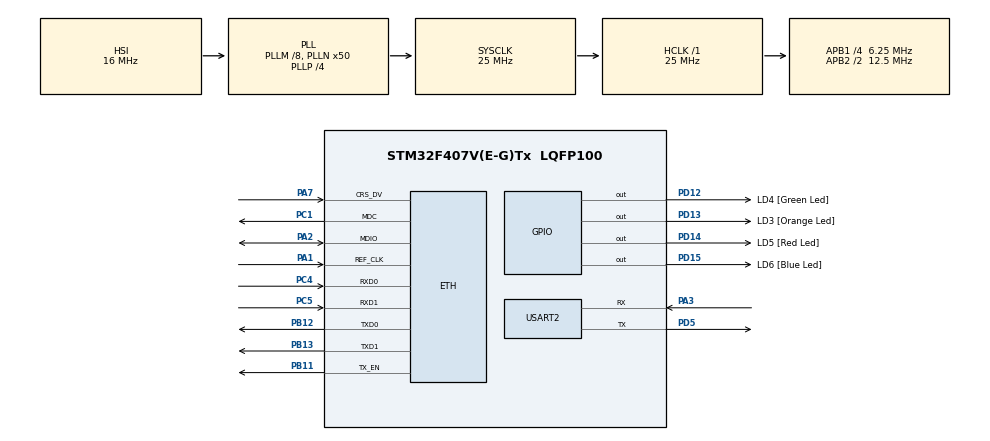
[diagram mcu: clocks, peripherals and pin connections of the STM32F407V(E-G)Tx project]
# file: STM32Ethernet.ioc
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Dma.Request0=USART2_TX
Dma.USART2_TX.0.Direction=DMA_MEMORY_TO_PERIPH
Dma.USART2_TX.0.FIFOMode=DMA_FIFOMODE_DISABLE
Dma.USART2_TX.0.Instance=DMA1_Stream6
Dma.USART2_TX.0.MemDataAlignment=DMA_MDATAALIGN_BYTE
Dma.USART2_TX.0.MemInc=DMA_MINC_ENABLE
Dma.USART2_TX.0.Mode=DMA_NORMAL
Dma.USART2_TX.0.PeriphDataAlignment=DMA_PDATAALIGN_BYTE
Dma.USART2_TX.0.PeriphInc=DMA_PINC_DISABLE
Dma.USART2_TX.0.Priority=DMA_PRIORITY_LOW
ETH.MediaInterface=ETH_MEDIA_INTERFACE_RMII
LWIP.API_LIB_DEBUG=LWIP_DBG_ON
LWIP.API_MSG_DEBUG=LWIP_DBG_ON
LWIP.ETHARP_DEBUG=LWIP_DBG_ON
LWIP.GATEWAY_ADDRESS=192.168.000.001
LWIP.ICMP_DEBUG=LWIP_DBG_ON
LWIP.IGMP_DEBUG=LWIP_DBG_ON
LWIP.INET_DEBUG=LWIP_DBG_ON
LWIP.IP_ADDRESS=192.168.000.046
LWIP.IP_DEBUG=LWIP_DBG_ON
LWIP.IP_REASS_DEBUG=LWIP_DBG_ON
LWIP.LWIP_DHCP=1
LWIP.LWIP_TCP=0
LWIP.MEMP_DEBUG=LWIP_DBG_ON
LWIP.MEM_DEBUG=LWIP_DBG_ON
LWIP.NETIF_DEBUG=LWIP_DBG_ON
LWIP.NETMASK_ADDRESS=255.255.255.000
LWIP.PBUF_DEBUG=LWIP_DBG_ON
LWIP.RAW_DEBUG=LWIP_DBG_ON
LWIP.SOCKETS_DEBUG=LWIP_DBG_ON
LWIP.SYS_DEBUG=LWIP_DBG_ON
LWIP.TCP_DEBUG=LWIP_DBG_ON
LWIP.TCP_FR_DEBUG=LWIP_DBG_ON
LWIP.TCP_INPUT_DEBUG=LWIP_DBG_ON
LWIP.TIMERS_DEBUG=LWIP_DBG_ON
LWIP.Version=v2.1.2_Cube
Mcu.Family=STM32F4
Mcu.Name=STM32F407V(E-G)Tx
Mcu.Package=LQFP100
NVIC.DMA1_Stream6_IRQn=true\:0\:0\:false\:false\:true\:false\:true
NVIC.PriorityGroup=NVIC_PRIORITYGROUP_0
NVIC.USART2_IRQn=true\:0\:0\:false\:false\:true\:true\:true
PA1.Mode=RMII
PA1.Signal=ETH_REF_CLK
PA2.Mode=RMII
PA2.Signal=ETH_MDIO
PA3.Mode=Asynchronous
PA3.Signal=USART2_RX
PA7.Mode=RMII
PA7.Signal=ETH_CRS_DV
PB11.Mode=RMII
PB11.Signal=ETH_TX_EN
PB12.Mode=RMII
PB12.Signal=ETH_TXD0
PB13.Mode=RMII
PB13.Signal=ETH_TXD1
PC1.Mode=RMII
PC1.Signal=ETH_MDC
PC4.Mode=RMII
PC4.Signal=ETH_RXD0
PC5.Mode=RMII
PC5.Signal=ETH_RXD1
PD12.GPIO_Label=LD4 [Green Led]
PD12.GPIO_PuPd=GPIO_NOPULL
PD12.GPIO_Speed=GPIO_SPEED_FREQ_LOW
PD12.Signal=GPIO_Output
PD13.GPIO_Label=LD3 [Orange Led]
PD13.GPIO_PuPd=GPIO_NOPULL
PD13.GPIO_Speed=GPIO_SPEED_FREQ_LOW
PD13.Signal=GPIO_Output
PD14.GPIO_Label=LD5 [Red Led]
PD14.GPIO_PuPd=GPIO_NOPULL
PD14.GPIO_Speed=GPIO_SPEED_FREQ_LOW
PD14.Signal=GPIO_Output
PD15.GPIO_Label=LD6 [Blue Led]
PD15.GPIO_PuPd=GPIO_NOPULL
PD15.GPIO_Speed=GPIO_SPEED_FREQ_LOW
PD15.Signal=GPIO_Output
PD5.Mode=Asynchronous
PD5.Signal=USART2_TX
ProjectManager.HeapSize=0x200
ProjectManager.StackSize=0x400
ProjectManager.TargetToolchain=STM32CubeIDE
RCC.48MHZClocksFreq_Value=14285714.285714285
RCC.AHBFreq_Value=25000000
RCC.APB1CLKDivider=RCC_HCLK_DIV4
RCC.APB1Freq_Value=6250000
RCC.APB1TimFreq_Value=12500000
RCC.APB2CLKDivider=RCC_HCLK_DIV2
RCC.APB2Freq_Value=12500000
RCC.APB2TimFreq_Value=25000000
RCC.CortexFreq_Value=25000000
RCC.HCLKFreq_Value=25000000
RCC.HSE_VALUE=8000000
RCC.HSI_VALUE=16000000
RCC.LSE_VALUE=32768
RCC.PLLM=8
RCC.PLLN=50
RCC.PLLP=RCC_PLLP_DIV4
RCC.PLLQ=7
RCC.SYSCLKFreq_VALUE=25000000
RCC.SYSCLKSource=RCC_SYSCLKSOURCE_PLLCLK
RCC.VCOOutputFreq_Value=100000000
USART2.VirtualMode=VM_ASYNC
VP_LWIP_VS_Enabled.Mode=Enabled
board=STM32F407G-DISC1

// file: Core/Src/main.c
/* USER CODE BEGIN Header */
/**
  ******************************************************************************
  * @file           : main.c
  * @brief          : Main program body
  ******************************************************************************
  * @attention
  *
  * <h2><center>&copy; Copyright (c) 2020 STMicroelectronics.
  * All rights reserved.</center></h2>
  *
  * This software component is licensed by ST under BSD 3-Clause license,
  * the "License"; You may not use this file except in compliance with the
  * License. You may obtain a copy of the License at:
  *                        opensource.org/licenses/BSD-3-Clause
  *
  ******************************************************************************
  */
/* USER CODE END Header */

#include "main.h"
#include "lwip.h"
#include "retarget.h"

/* USER CODE BEGIN Includes */
#include <string.h>
#include "lwip/udp.h"
#include "lwip/debug.h"
//#include "udp_echo_server.h"
//#include "udp_qotd_client.h"
#include "tcp_echo_server.h"
/* USER CODE END Includes */

UART_HandleTypeDef huart2;
DMA_HandleTypeDef hdma_usart2_tx;

/* USER CODE BEGIN PV */
extern struct netif gnetif;
struct udp_pcb * udp_app_pcb_p;

/* USER CODE END PV */

void SystemClock_Config(void);
static void MX_GPIO_Init(void);
static void MX_DMA_Init(void);
static void MX_USART2_UART_Init(void);

/* USER CODE BEGIN 0 */
//extern uint8_t req_sent;
/* USER CODE END 0 */

int main(void)
{

  /* MCU Configuration--------------------------------------------------------*/

  /* Reset of all peripherals, Initializes the Flash interface and the Systick. */
  HAL_Init();

  /* Configure the system clock */
  SystemClock_Config();

  /* Initialize all configured peripherals */
  MX_GPIO_Init();
  MX_DMA_Init();
  MX_USART2_UART_Init();
  MX_LWIP_Init();

  /* USER CODE BEGIN 2 */

//  udp_app_init();
//  udp_app_send();
// udp_echo_init();
//  udp_echo_server_init();
//  udp_qotd_client_init();
  tcp_echo_server_init();
  /* USER CODE END 2 */

  /* Infinite loop */
  /* USER CODE BEGIN WHILE */
  while (1)
  {
	//HAL_UART_Transmit_DMA(&huart2, (uint8_t *)USART_test_msg, strlen(USART_test_msg));
    /* USER CODE END WHILE */

    /* USER CODE BEGIN 3 */
	  ethernetif_input(&gnetif);
	  sys_check_timeouts();
//	  if(req_sent < 1) {
//		  udp_qotd_req();
//	  }

  }
  /* USER CODE END 3 */
}

void SystemClock_Config(void)
{
  RCC_OscInitTypeDef RCC_OscInitStruct = {0};
  RCC_ClkInitTypeDef RCC_ClkInitStruct = {0};

  /** Configure the main internal regulator output voltage
  */
  __HAL_RCC_PWR_CLK_ENABLE();
  __HAL_PWR_VOLTAGESCALING_CONFIG(PWR_REGULATOR_VOLTAGE_SCALE1);
  /** Initializes the CPU, AHB and APB busses clocks
  */
  RCC_OscInitStruct.OscillatorType = RCC_OSCILLATORTYPE_HSI;
  RCC_OscInitStruct.HSIState = RCC_HSI_ON;
  RCC_OscInitStruct.HSICalibrationValue = RCC_HSICALIBRATION_DEFAULT;
  RCC_OscInitStruct.PLL.PLLState = RCC_PLL_ON;
  RCC_OscInitStruct.PLL.PLLSource = RCC_PLLSOURCE_HSI;
  RCC_OscInitStruct.PLL.PLLM = 8;
  RCC_OscInitStruct.PLL.PLLN = 50;
  RCC_OscInitStruct.PLL.PLLP = RCC_PLLP_DIV4;
  RCC_OscInitStruct.PLL.PLLQ = 7;
  if (HAL_RCC_OscConfig(&RCC_OscInitStruct) != HAL_OK)
  {
    Error_Handler();
  }
  /** Initializes the CPU, AHB and APB busses clocks
  */
  RCC_ClkInitStruct.ClockType = RCC_CLOCKTYPE_HCLK|RCC_CLOCKTYPE_SYSCLK
                              |RCC_CLOCKTYPE_PCLK1|RCC_CLOCKTYPE_PCLK2;
  RCC_ClkInitStruct.SYSCLKSource = RCC_SYSCLKSOURCE_PLLCLK;
  RCC_ClkInitStruct.AHBCLKDivider = RCC_SYSCLK_DIV1;
  RCC_ClkInitStruct.APB1CLKDivider = RCC_HCLK_DIV4;
  RCC_ClkInitStruct.APB2CLKDivider = RCC_HCLK_DIV2;

  if (HAL_RCC_ClockConfig(&RCC_ClkInitStruct, FLASH_LATENCY_0) != HAL_OK)
  {
    Error_Handler();
  }
}

static void MX_USART2_UART_Init(void)
{

  huart2.Instance = USART2;
  huart2.Init.BaudRate = 115200;
  huart2.Init.WordLength = UART_WORDLENGTH_8B;
  huart2.Init.StopBits = UART_STOPBITS_1;
  huart2.Init.Parity = UART_PARITY_NONE;
  huart2.Init.Mode = UART_MODE_TX_RX;
  huart2.Init.HwFlowCtl = UART_HWCONTROL_NONE;
  huart2.Init.OverSampling = UART_OVERSAMPLING_16;
  if (HAL_UART_Init(&huart2) != HAL_OK)
  {
    Error_Handler();
  }

}

static void MX_DMA_Init(void)
{

  /* DMA controller clock enable */
  __HAL_RCC_DMA1_CLK_ENABLE();

  /* DMA interrupt init */
  /* DMA1_Stream6_IRQn interrupt configuration */
  HAL_NVIC_SetPriority(DMA1_Stream6_IRQn, 0, 0);
  HAL_NVIC_EnableIRQ(DMA1_Stream6_IRQn);

}

static void MX_GPIO_Init(void)
{
  GPIO_InitTypeDef GPIO_InitStruct = {0};

  /* GPIO Ports Clock Enable */
  __HAL_RCC_GPIOC_CLK_ENABLE();
  __HAL_RCC_GPIOA_CLK_ENABLE();
  __HAL_RCC_GPIOB_CLK_ENABLE();
  __HAL_RCC_GPIOD_CLK_ENABLE();

  /*Configure GPIO pin Output Level */
  HAL_GPIO_WritePin(GPIOD, LD4_Pin|LD3_Pin|LD5_Pin|LD6_Pin, GPIO_PIN_RESET);

  /*Configure GPIO pins : LD4_Pin LD3_Pin LD5_Pin LD6_Pin */
  GPIO_InitStruct.Pin = LD4_Pin|LD3_Pin|LD5_Pin|LD6_Pin;
  GPIO_InitStruct.Mode = GPIO_MODE_OUTPUT_PP;
  GPIO_InitStruct.Pull = GPIO_NOPULL;
  GPIO_InitStruct.Speed = GPIO_SPEED_FREQ_LOW;
  HAL_GPIO_Init(GPIOD, &GPIO_InitStruct);

}

void Error_Handler(void)
{
}

/************************ (C) COPYRIGHT STMicroelectronics *****END OF FILE****/
